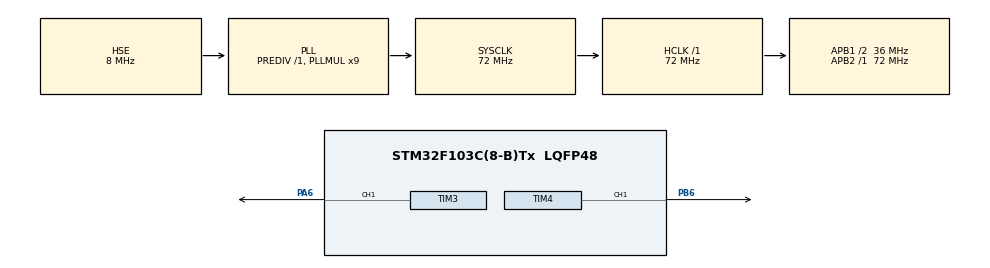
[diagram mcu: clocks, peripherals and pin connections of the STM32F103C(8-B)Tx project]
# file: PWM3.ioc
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Mcu.Family=STM32F1
Mcu.Name=STM32F103C(8-B)Tx
Mcu.Package=LQFP48
NVIC.PriorityGroup=NVIC_PRIORITYGROUP_4
PA13.Mode=Serial_Wire
PA13.Signal=SYS_JTMS-SWDIO
PA14.Mode=Serial_Wire
PA14.Signal=SYS_JTCK-SWCLK
PA6.Signal=S_TIM3_CH1
PB6.Signal=S_TIM4_CH1
PD0-OSC_IN.Mode=HSE-External-Oscillator
PD0-OSC_IN.Signal=RCC_OSC_IN
PD1-OSC_OUT.Mode=HSE-External-Oscillator
PD1-OSC_OUT.Signal=RCC_OSC_OUT
ProjectManager.HeapSize=0x200
ProjectManager.StackSize=0x400
ProjectManager.TargetToolchain=MDK-ARM V5
RCC.AHBFreq_Value=72000000
RCC.APB1CLKDivider=RCC_HCLK_DIV2
RCC.APB1Freq_Value=36000000
RCC.APB1TimFreq_Value=72000000
RCC.APB2Freq_Value=72000000
RCC.APB2TimFreq_Value=72000000
RCC.HCLKFreq_Value=72000000
RCC.PLLMUL=RCC_PLL_MUL9
RCC.PLLSourceVirtual=RCC_PLLSOURCE_HSE
RCC.SYSCLKFreq_VALUE=72000000
RCC.SYSCLKSource=RCC_SYSCLKSOURCE_PLLCLK
RCC.USBFreq_Value=72000000
SH.S_TIM3_CH1.0=TIM3_CH1,PWM Generation1 CH1
SH.S_TIM4_CH1.0=TIM4_CH1,PWM Generation1 CH1
TIM3.Channel-PWM\ Generation1\ CH1=TIM_CHANNEL_1
TIM3.Period=500
TIM3.Prescaler=71
TIM4.Channel-PWM\ Generation1\ CH1=TIM_CHANNEL_1
TIM4.Period=500
TIM4.Prescaler=71
board=custom

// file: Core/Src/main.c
/* USER CODE BEGIN Header */
/**
  ******************************************************************************
  * @file           : main.c
  * @brief          : Main program body
  ******************************************************************************
  * @attention
  *
  * Copyright (c) 2025 STMicroelectronics.
  * All rights reserved.
  *
  * This software is licensed under terms that can be found in the LICENSE file
  * in the root directory of this software component.
  * If no LICENSE file comes with this software, it is provided AS-IS.
  *
  ******************************************************************************
  */
/* USER CODE END Header */
#include "main.h"
#include "tim.h"
#include "gpio.h"

/* USER CODE BEGIN PD */
#define PWM_PERIOD 0.5f  // PWM周期0.5ms
#define DELAY_MS 1      // 占空比变化延迟时间
/* USER CODE END PD */

/* USER CODE BEGIN PV */
uint16_t tim3_duty = 0;   // TIM3占空比
uint16_t tim4_duty = 0;   // TIM4占空比
int8_t tim3_dir = 1;      // TIM3占空比变化方向(1:增大, -1:减小)
int8_t tim4_dir = 1;      // TIM4占空比变化方向(1:增大, -1:减小)
/* USER CODE END PV */

void SystemClock_Config(void);

int main(void)
{

  /* MCU Configuration--------------------------------------------------------*/

  /* Reset of all peripherals, Initializes the Flash interface and the Systick. */
  HAL_Init();

  /* Configure the system clock */
  SystemClock_Config();

  /* Initialize all configured peripherals */
  MX_GPIO_Init();
  MX_TIM3_Init();
  MX_TIM4_Init();
  /* USER CODE BEGIN 2 */
  // 启动TIM3和TIM4的PWM输出
  HAL_TIM_PWM_Start(&htim3, TIM_CHANNEL_1);  // TIM3通道1(PA6)
  HAL_TIM_PWM_Start(&htim4, TIM_CHANNEL_1);  // TIM4通道1(通过PB6控制PC13)
  /* USER CODE END 2 */

  /* Infinite loop */
  while (1)
  {

    /* USER CODE BEGIN 3 */
    // 更新TIM3占空比
    __HAL_TIM_SET_COMPARE(&htim3, TIM_CHANNEL_1, tim3_duty);
    // 更新TIM4占空比
    __HAL_TIM_SET_COMPARE(&htim4, TIM_CHANNEL_1, tim4_duty);

    // 改变占空比，实现呼吸效果
    tim3_duty += tim3_dir;
    tim4_duty += tim4_dir;

    // 反转TIM3占空比变化方向
    if (tim3_duty >= htim3.Instance->ARR) {
      tim3_dir = -1;
    } else if (tim3_duty <= 0) {
      tim3_dir = 1;
    }

    // 反转TIM4占空比变化方向
    if (tim4_duty >= htim4.Instance->ARR) {
      tim4_dir = -1;
    } else if (tim4_duty <= 0) {
      tim4_dir = 1;
    }

    // 延迟一段时间，控制呼吸速度
    HAL_Delay(DELAY_MS);
  }
  /* USER CODE END 3 */
}

void SystemClock_Config(void)
{
  RCC_OscInitTypeDef RCC_OscInitStruct = {0};
  RCC_ClkInitTypeDef RCC_ClkInitStruct = {0};

  /** Initializes the RCC Oscillators according to the specified parameters
  * in the RCC_OscInitTypeDef structure.
  */
  RCC_OscInitStruct.OscillatorType = RCC_OSCILLATORTYPE_HSE;
  RCC_OscInitStruct.HSEState = RCC_HSE_ON;
  RCC_OscInitStruct.HSEPredivValue = RCC_HSE_PREDIV_DIV1;
  RCC_OscInitStruct.HSIState = RCC_HSI_ON;
  RCC_OscInitStruct.PLL.PLLState = RCC_PLL_ON;
  RCC_OscInitStruct.PLL.PLLSource = RCC_PLLSOURCE_HSE;
  RCC_OscInitStruct.PLL.PLLMUL = RCC_PLL_MUL9;
  if (HAL_RCC_OscConfig(&RCC_OscInitStruct) != HAL_OK)
  {
    Error_Handler();
  }

  /** Initializes the CPU, AHB and APB buses clocks
  */
  RCC_ClkInitStruct.ClockType = RCC_CLOCKTYPE_HCLK|RCC_CLOCKTYPE_SYSCLK
                              |RCC_CLOCKTYPE_PCLK1|RCC_CLOCKTYPE_PCLK2;
  RCC_ClkInitStruct.SYSCLKSource = RCC_SYSCLKSOURCE_PLLCLK;
  RCC_ClkInitStruct.AHBCLKDivider = RCC_SYSCLK_DIV1;
  RCC_ClkInitStruct.APB1CLKDivider = RCC_HCLK_DIV2;
  RCC_ClkInitStruct.APB2CLKDivider = RCC_HCLK_DIV1;

  if (HAL_RCC_ClockConfig(&RCC_ClkInitStruct, FLASH_LATENCY_2) != HAL_OK)
  {
    Error_Handler();
  }
}

void Error_Handler(void)
{
  __disable_irq();
  while (1)
  {
  }
}
